# RL6842_IP_SVD register map
Vendor: Realtek
Registers are 32-bit, read-write, reset 0x0 unless marked. A register's access mark holds for its fields unless they carry their own. Offsets are from the block's base; [hi:lo] are bit positions; {n}, {i} and the like mark numbered series.

## RSIP_REG
Base 0x4100CA00
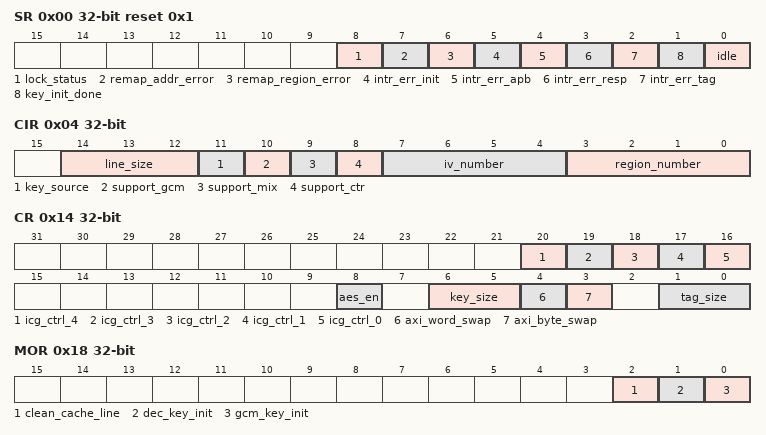
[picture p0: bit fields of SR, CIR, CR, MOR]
0x00 SR ro reset 0x1 — Status Register
  [8] lock_status — Indicates whether the setting is locked. If it is locked, only clr_intr and Maintenance registers can be set.
  [7] remap_addr_error — Indicates the address after adding offset size cross 256MB boundaries
  [6] remap_region_error — Indicates the read address hits multiple remapping region.
  [5] intr_err_init — Indicates the transaction was received before the key initialization is completed.
  [4] intr_err_apb — Indicates whether the setting configuration failed. When a transaction is in progress, all settings except clear interruption are invalid.
  [3] intr_err_resp — Indicates the error response is received from slave.
  [2] intr_err_tag — Indicates a GCM tag mismatch error occurred.
  [1] key_init_done — Indicates whether the initialization of the key is completed. Only used in GCM and MIX mode.
  [0] idle — Indicates whether there is any outstanding transaction.
0x04 CIR ro — Component Identification Register
  [14:12] line_size — Cache line size 0: 16B = 1 AES block 1: 32B = 2 AES blocks 2: 64B = 4 AES blocks 3: 128B = 8 AES blocks Indicates how many 128-bit blocks are used to calculate the tag cache line size (byte) = 16 * 2BLOCK_SIZE
  [11] key_source — Indicates the key source 0: from dedicated key port (only supporting this configuration currently) 1: from APB register
  [10] support_gcm — Indicates whether GCM mode is supported.
  [9] support_mix — Indicates whether MIX mode is supported.
  [8] support_ctr — Indicates whether CTR mode is supported.
  [7:4] iv_number — Number of supported IVs registers
  [3:0] region_number — Number of supported decryption regions
0x08 EALR ro — Error Address Log Register
  [31:0] error_address — Recorded address when GCM Tag mismatch error or receiving an error response.
0x10 ICR wo — Interrupt Clear Register
  [0] clr_intr — Interrupt clear It has to write 1'b1 to this register every time when the error exception occurs.
0x14 CR — Control Register
  [20] icg_ctrl_4 — Disable key-reg auto clock gating
  [19] icg_ctrl_3 — Disable apb-ctrl auto clock gating
  [18] icg_ctrl_2 — Disable aes-engine auto clock gating
  [17] icg_ctrl_1 — Disable fetch-unit auto clock gating
  [16] icg_ctrl_0 — Disable line-buffer auto clock gating
  [8] aes_en — Determine whether to enable the AES engine 0: Disable decryption engine (expect remapping function) 1: Enable decryption engine and line buffer
  [6:5] key_size — Determine the size of KEY 0: 128 bits 1: 192 bits 2: 256 bits
  [4] axi_word_swap — Determine the endian of ciphertext in slave memory. Setting to 1 can swap word order.
  [3] axi_byte_swap — Determine the endian of ciphertext in slave memory. Setting to 1 can swap byte order.
  [1:0] tag_size — The size of the tag will affect the length of each tag command. 0: 32 bits 1: 64 bits 2: 128bits
0x18 MOR wo — Maintenance Operation Register
  [2] clean_cache_line — Manually clear the line buffer. Write 1 to clear all after flash data update.
  [1] dec_key_init — Only used in MIX mode. Whenever the key is changed, write 1 to this bit to initialize the decryption key. When keys are update by external port, sec engine will trigger this bit automatically. The status of completion can be determined by reading bit 1 of the status register.
  [0] gcm_key_init — Only used in GCM mode. Whenever the key is changed, write 1 to initialize the GMAC key. When keys are update by external port, sec engine will trigger this bit automatically. The status of completion can be determined by reading bit 1 of the status register.
0x1C LR wo — Lock Register
  [7:0] lock — When this field is set to 0xDC, all registers except clr_intr and Maintenance are not allowed to be written.
0x20 TBAR — GCM Tag Base Address Register
  [31:0] tag_base_0 — Tag base address in flash memory
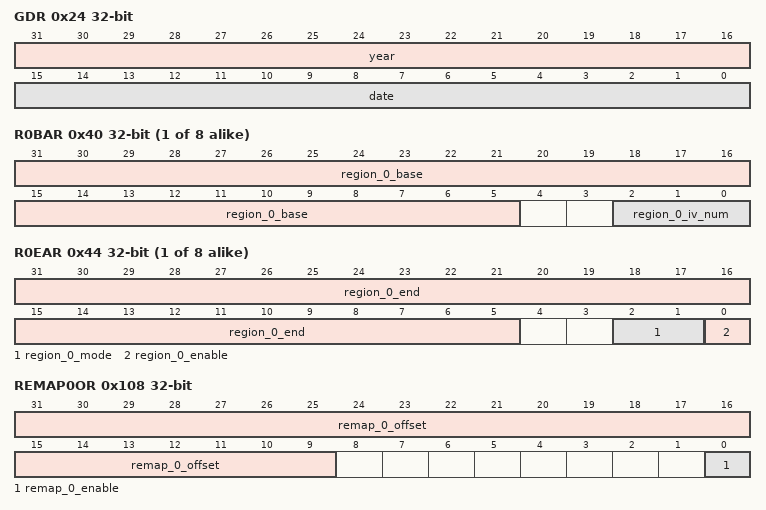
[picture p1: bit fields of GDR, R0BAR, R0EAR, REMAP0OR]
0x24 GDR ro — Gen Date Register
  [31:16] year — Year of code generation
  [15:0] date — Date of code generation
0x28 VR ro — Version Register
  [31:0] version — Version of code generation
{0x40+8i} R{i}BAR (i=0..7)
  [31:5] region_{i}_base — Region {i} base address register
  [2:0] region_{i}_iv_num — IV used in region {i} Apply which IV reigster to this region Number corresponds to IV register
{0x44+8i} R{i}EAR (i=0..7)
  [31:5] region_{i}_end — Region {i} end address register
  [2:1] region_{i}_mode — Mode used in region {i} 2'b00: GCM mode 2'b01: CTR mode 2'b10: MIX mode 2'b11: Reserved
  [0] region_{i}_enable — Enable region {i} setting
{0x80+8i} IV{i}L (i=0..7)
  [31:0] iv_{i}_high — Fixed field of IV value iv_{i}[127:96] IV = iv_{i}_high32 || iv_{i}_low32 || (address >> (4+(LINE_SIZE/32)-1))32 || (address[4+(LINE_SIZE/32)-2:0] + 2)32
{0x84+8i} IV{i}H (i=0..7)
  [31:0] iv_{i}_low — Fixed field of IV value iv_{i}[95:64] IV = iv_{i}_high32 || iv_{i}_low32 || (address >> (4+(LINE_SIZE/32)-1))32 || (address[4+(LINE_SIZE/32)-2:0] + 2)32
0x100 REMAP0BAR
  [31:9] remap_base_0_addr — Remap region 0 base address [27:5] Region_Base_Addr = {flash_base[31:28], remap_base_0_addr, 5'b0} The region address is 32B aligned, and not cross 256KB.
0x104 REMAP0EAR
  [31:9] remap_end_0_offset — Remap region 0 end address [27:5] Region_Base_Addr = {flash_base[31:28], remap_end_0_addr, 5'b0} The region address is 32B aligned, and not cross 256KB.
0x108 REMAP0OR
  [31:9] remap_0_offset — Remap region 0 offset [27:5] Region_Offset = {4'b0,remap_0_offset, 5'b0} The output address is "Access address - Region_Base_Addr + Region_Offset".
  [0] remap_0_enable — Remap region 0 enable
0x10C REMAP1BAR
  [31:9] remap_base_1_addr — Remap region 1 base address [27:5] Region_Base_Addr = {flash_base[31:28], remap_base_1_addr, 5'b0} The region address is 32B aligned, and not cross 256KB.
0x110 REMAP1EAR
  [31:9] remap_end_1_offset — Remap region 1 end address [27:5] Region_Base_Addr = {flash_base[31:28], remap_end_1_addr, 5'b0} The region address is 32B aligned, and not cross 256KB.
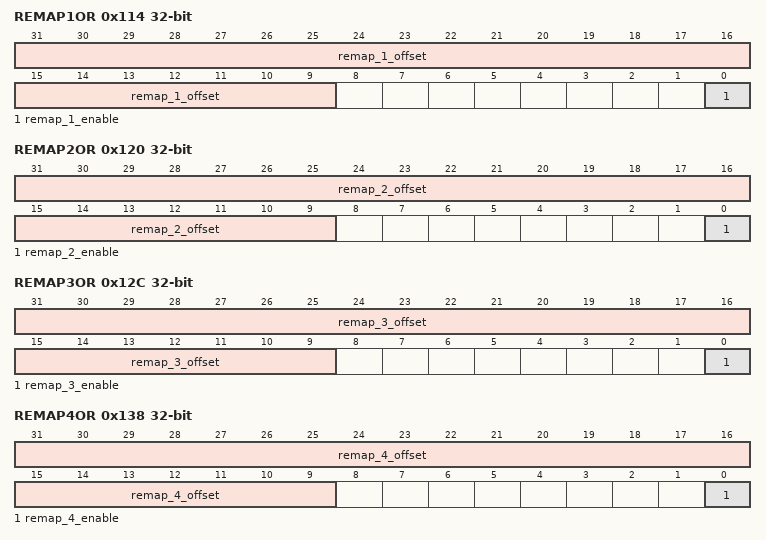
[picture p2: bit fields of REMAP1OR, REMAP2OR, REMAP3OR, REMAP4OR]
0x114 REMAP1OR
  [31:9] remap_1_offset — Remap region 1 offset [27:5] Region_Offset = {4'b0,remap_1_offset, 5'b0} The output address is "Access address - Region_Base_Addr + Region_Offset".
  [0] remap_1_enable — Remap region 1 enable
0x118 REMAP2BAR
  [31:9] remap_base_2_addr — Remap region 2 base address [27:5] Region_Base_Addr = {flash_base[31:28], remap_base_2_addr, 5'b0} The region address is 32B aligned, and not cross 256KB.
0x11C REMAP2EAR
  [31:9] remap_end_2_offset — Remap region 2 end address [27:5] Region_Base_Addr = {flash_base[31:28], remap_end_2_addr, 5'b0} The region address is 32B aligned, and not cross 256KB.
0x120 REMAP2OR
  [31:9] remap_2_offset — Remap region 2 offset [27:5] Region_Offset = {4'b0,remap_2_offset, 5'b0} The output address is "Access address - Region_Base_Addr + Region_Offset".
  [0] remap_2_enable — Remap region 2 enable
0x124 REMAP3BAR
  [31:9] remap_base_3_addr — Remap region 3 base address [27:5] Region_Base_Addr = {flash_base[31:28], remap_base_3_addr, 5'b0} The region address is 32B aligned, and not cross 256KB.
0x128 REMAP3EAR
  [31:9] remap_end_3_offset — Remap region 3 end address [27:5] Region_Base_Addr = {flash_base[31:28], remap_end_3_addr, 5'b0} The region address is 32B aligned, and not cross 256KB.
0x12C REMAP3OR
  [31:9] remap_3_offset — Remap region 3 offset [27:5] Region_Offset = {4'b0,remap_3_offset, 5'b0} The output address is "Access address - Region_Base_Addr + Region_Offset".
  [0] remap_3_enable — Remap region 3 enable
0x130 REMAP4BAR
  [31:9] remap_base_4_addr — Remap region 4 base address [27:5] Region_Base_Addr = {flash_base[31:28], remap_base_4_addr, 5'b0} The region address is 32B aligned, and not cross 256KB.
0x134 REMAP4EAR
  [31:9] remap_end_4_offset — Remap region 4 end address [27:5] Region_Base_Addr = {flash_base[31:28], remap_end_4_addr, 5'b0} The region address is 32B aligned, and not cross 256KB.
0x138 REMAP4OR
  [31:9] remap_4_offset — Remap region 4 offset [27:5] Region_Offset = {4'b0,remap_4_offset, 5'b0} The output address is "Access address - Region_Base_Addr + Region_Offset".
  [0] remap_4_enable — Remap region 4 enable
0x13C REMAP5BAR
  [31:9] remap_base_5_addr — Remap region 5 base address [27:5] Region_Base_Addr = {flash_base[31:28], remap_base_5_addr, 5'b0} The region address is 32B aligned, and not cross 256KB.
0x140 REMAP5EAR
  [31:9] remap_end_5_offset — Remap region 5 end address [27:5] Region_Base_Addr = {flash_base[31:28], remap_end_5_addr, 5'b0} The region address is 32B aligned, and not cross 256KB.
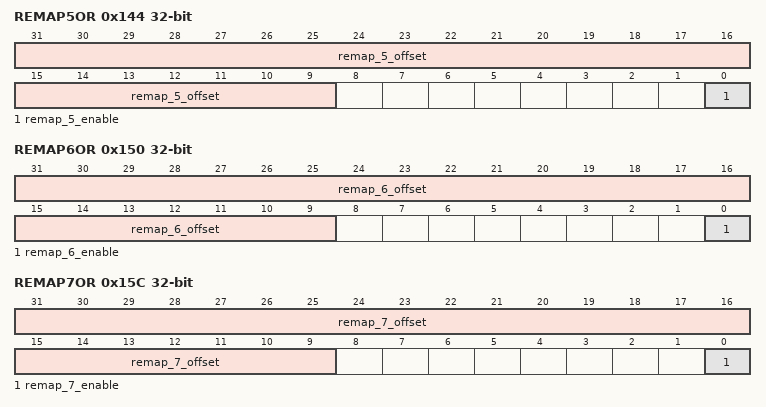
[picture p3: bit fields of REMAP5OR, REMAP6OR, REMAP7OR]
0x144 REMAP5OR
  [31:9] remap_5_offset — Remap region 5 offset [27:5] Region_Offset = {4'b0,remap_5_offset, 5'b0} The output address is "Access address - Region_Base_Addr + Region_Offset".
  [0] remap_5_enable — Remap region 5 enable
0x148 REMAP6BAR
  [31:9] remap_base_6_addr — Remap region 6 base address [27:5] Region_Base_Addr = {flash_base[31:28], remap_base_6_addr, 5'b0} The region address is 32B aligned, and not cross 256KB.
0x14C REMAP6EAR
  [31:9] remap_end_6_offset — Remap region 6 end address [27:5] Region_Base_Addr = {flash_base[31:28], remap_end_6_addr, 5'b0} The region address is 32B aligned, and not cross 256KB.
0x150 REMAP6OR
  [31:9] remap_6_offset — Remap region 6 offset [27:5] Region_Offset = {4'b0,remap_6_offset, 5'b0} The output address is "Access address - Region_Base_Addr + Region_Offset".
  [0] remap_6_enable — Remap region 6 enable
0x154 REMAP7BAR
  [31:9] remap_base_7_addr — Remap region 7 base address [27:5] Region_Base_Addr = {flash_base[31:28], remap_base_7_addr, 5'b0} The region address is 32B aligned, and not cross 256KB.
0x158 REMAP7EAR
  [31:9] remap_end_7_offset — Remap region 7 end address [27:5] Region_Base_Addr = {flash_base[31:28], remap_end_7_addr, 5'b0} The region address is 32B aligned, and not cross 256KB.
0x15C REMAP7OR
  [31:9] remap_7_offset — Remap region 7 offset [27:5] Region_Offset = {4'b0,remap_7_offset, 5'b0} The output address is "Access address - Region_Base_Addr + Region_Offset".
  [0] remap_7_enable — Remap region 7 enable
